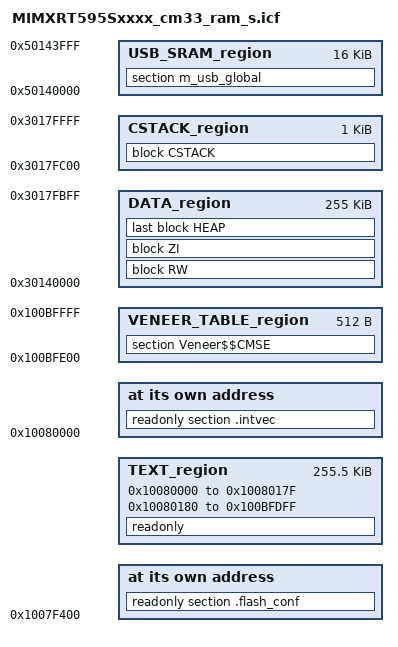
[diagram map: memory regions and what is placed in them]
/*
** ###################################################################
**     Processor:           MIMXRT595SFFOA_cm33
**     Compiler:            IAR ANSI C/C++ Compiler for ARM
**     Reference manual:    RT500 Reference Manual. Rev.0,07/2019
**     Version:             rev. 2.0, 2019-07-22
**     Build:               b190723
**
**     Abstract:
**         Linker file for the IAR ANSI C/C++ Compiler for ARM
**
**     Copyright 2016 Freescale Semiconductor, Inc.
**     Copyright 2016-2019 NXP
**     All rights reserved.
**
**     SPDX-License-Identifier: BSD-3-Clause
**
**     http:                 www.nxp.com
**     mail:                 support@nxp.com
**
** ###################################################################
*/

/* USB BDT size */
define symbol usb_bdt_size             = 0x0;
/* Stack and Heap Sizes */
if (isdefinedsymbol(__stack_size__)) {
  define symbol __size_cstack__        = __stack_size__;
} else {
  define symbol __size_cstack__        = 0x0400;
}

if (isdefinedsymbol(__heap_size__)) {
  define symbol __size_heap__          = __heap_size__;
} else {
  define symbol __size_heap__          = 0x0400;
}

/* The SRAM region [0x0-0x20000] is reserved for ROM code and app-specific use cases. */
/* The SRAM region [0x20000-0x80000] is reserved for Non-cached shared memory between M33 and DSP. */
/* Only the first 256kB is used as secure SRAM memory. */

define symbol m_interrupts_start               = 0x10080000;
define symbol m_interrupts_end                 = 0x1008017F;

define symbol m_text_start                     = 0x10080180;
define symbol m_text_end                       = 0x100BFDFF;

/* Only first 256kB of data RAM is used as secure memory. */
define symbol m_data_start                     = 0x30140000;
define symbol m_data_end                       = 0x3017FFFF;

/* 512B - memory for veneer table (NSC - secure, non-secure callable memory) */
define symbol m_veneer_table_start             = 0x100BFE00;
define symbol m_veneer_table_size              = 0x00000200;

define symbol m_usb_sram_start                 = 0x50140000;
define symbol m_usb_sram_end                   = 0x50143FFF;

define symbol m_boot_flash_conf_start          = 0x1007F400;

define exported symbol __VECTOR_TABLE          = m_interrupts_start;
define exported symbol __VECTOR_RAM            = m_interrupts_start;
define exported symbol __RAM_VECTOR_TABLE_SIZE = 0x0;

define memory mem with size = 4G;

define region TEXT_region             = mem:[from m_interrupts_start to m_interrupts_end]
                                      | mem:[from m_text_start to m_text_end];
define region DATA_region             = mem:[from m_data_start to m_data_end - __size_cstack__];
define region CSTACK_region           = mem:[from m_data_end-__size_cstack__ + 1 to m_data_end];
define region VENEER_TABLE_region     = mem:[from m_veneer_table_start to m_veneer_table_start + m_veneer_table_size - 1];

define block CSTACK    with alignment = 8, size = __size_cstack__   { };
define block HEAP      with alignment = 8, size = __size_heap__     { };
define block RW        { readwrite };
define block ZI        { zi };

/* regions for USB */
define region USB_BDT_region = mem:[from m_usb_sram_start to m_usb_sram_start + usb_bdt_size - 1];
define region USB_SRAM_region = mem:[from m_usb_sram_start + usb_bdt_size to m_usb_sram_end];

initialize by copy { readwrite, section .textrw };

do not initialize  { section .noinit, section m_usb_bdt, section m_usb_global  };

keep{section .flash_conf };
place at address mem: m_boot_flash_conf_start    { readonly section .flash_conf };
place at address mem: m_interrupts_start    { readonly section .intvec };
place in TEXT_region                        { readonly };
place in DATA_region                        { block RW };
place in DATA_region                        { block ZI };
place in DATA_region                        { last block HEAP };
place in CSTACK_region                      { block CSTACK };
place in USB_BDT_region                     { section m_usb_bdt };
place in USB_SRAM_region                    { section m_usb_global };
place in VENEER_TABLE_region                { section Veneer$$CMSE };
